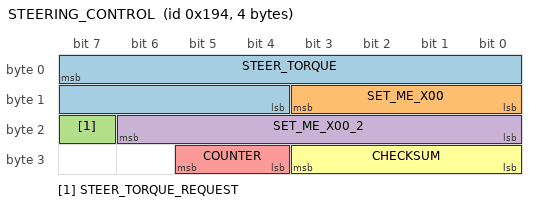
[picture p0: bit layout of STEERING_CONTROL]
BO_ 404 STEERING_CONTROL: 4 EON
 SG_ STEER_TORQUE : 7|12@0- (1,0) [-768|768] "" EPS
 SG_ SET_ME_X00 : 11|4@0+ (1,0) [0|15] "" EPS
 SG_ STEER_TORQUE_REQUEST : 23|1@0+ (1,0) [0|1] "" EPS
 SG_ SET_ME_X00_2 : 22|7@0+ (1,0) [0|127] "" EPS
 SG_ COUNTER : 29|2@0+ (1,0) [0|15] "" EPS
 SG_ CHECKSUM : 27|4@0+ (1,0) [0|3] "" EPS
